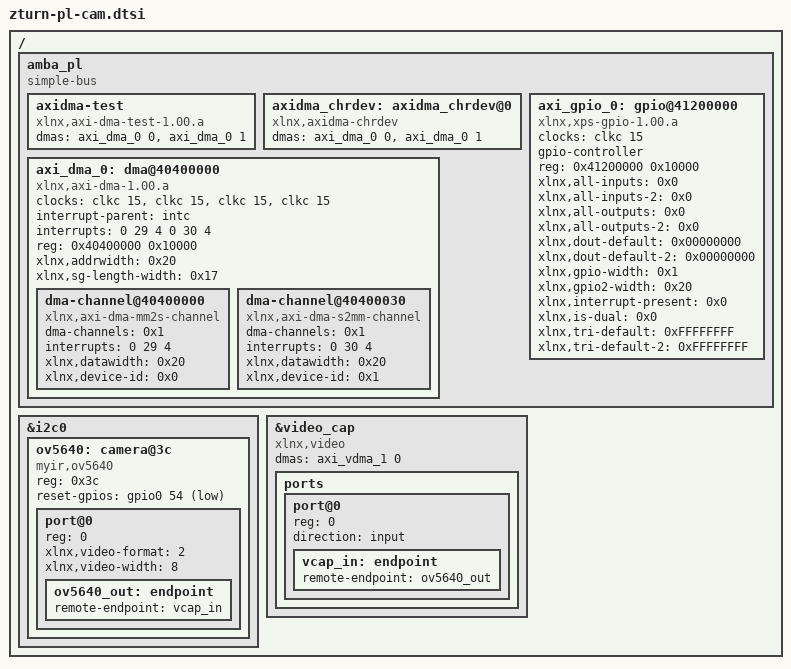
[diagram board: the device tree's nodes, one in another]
/*
 * CAUTION: This file is automatically generated by Xilinx.
 * Version:  
 * Today is: Mon Nov 19 09:26:09 2018
 */


/ {
	amba_pl: amba_pl {
		#address-cells = <1>;
		#size-cells = <1>;
		compatible = "simple-bus";
		ranges ;
		
		axidma-test{
			compatible = "xlnx,axi-dma-test-1.00.a";
			dmas = <&axi_dma_0 0 &axi_dma_0 1>;
			dma-names = "axidma0", "axidma1";
		};
		
		axidma_chrdev: axidma_chrdev@0 {
	    compatible = "xlnx,axidma-chrdev";
	    dmas = <&axi_dma_0 0 &axi_dma_0 1>;
	    dma-names = "tx_channel", "rx_channel";
		};
		
		axi_dma_0: dma@40400000 {
			#dma-cells = <1>;
			clock-names = "s_axi_lite_aclk", "m_axi_sg_aclk", "m_axi_mm2s_aclk", "m_axi_s2mm_aclk";
			clocks = <&clkc 15>, <&clkc 15>, <&clkc 15>, <&clkc 15>;
			compatible = "xlnx,axi-dma-1.00.a";
			interrupt-names = "mm2s_introut", "s2mm_introut";
			interrupt-parent = <&intc>;
			interrupts = <0 29 4 0 30 4>;
			reg = <0x40400000 0x10000>;
			xlnx,addrwidth = <0x20>;
			xlnx,sg-length-width = <0x17>;
			dma-channel@40400000 {
				compatible = "xlnx,axi-dma-mm2s-channel";
				dma-channels = <0x1>;
				interrupts = <0 29 4>;
				xlnx,datawidth = <0x20>;
				xlnx,device-id = <0x0>;
			};
			dma-channel@40400030 {
				compatible = "xlnx,axi-dma-s2mm-channel";
				dma-channels = <0x1>;
				interrupts = <0 30 4>;
				xlnx,datawidth = <0x20>;
				xlnx,device-id = <0x1>;
			};
		};
		
		axi_gpio_0: gpio@41200000 {
			#gpio-cells = <3>;
			clock-names = "s_axi_aclk";
			clocks = <&clkc 15>;
			compatible = "xlnx,xps-gpio-1.00.a";
			gpio-controller ;
			reg = <0x41200000 0x10000>;
			xlnx,all-inputs = <0x0>;
			xlnx,all-inputs-2 = <0x0>;
			xlnx,all-outputs = <0x0>;
			xlnx,all-outputs-2 = <0x0>;
			xlnx,dout-default = <0x00000000>;
			xlnx,dout-default-2 = <0x00000000>;
			xlnx,gpio-width = <0x1>;
			xlnx,gpio2-width = <0x20>;
			xlnx,interrupt-present = <0x0>;
			xlnx,is-dual = <0x0>;
			xlnx,tri-default = <0xFFFFFFFF>;
			xlnx,tri-default-2 = <0xFFFFFFFF>;
		};
		
	};

	&i2c0 {
		ov5640: camera@3c {
			compatible = "myir,ov5640";
			reg = <0x3c>;

			reset-gpios = <&gpio0 54 1>;

			status = "okay";

			#address-cells = <1>;
			#size-cells = <0>;

			port@0 {
				reg = <0>;

				xlnx,video-format = <2>;
				xlnx,video-width = <8>;

				ov5640_out: endpoint {
					remote-endpoint = <&vcap_in>;
				};
			};
		};

		// ov2659: camera@30 {
		// 	compatible = "myir,ov2659";
		// 	reg = <0x30>;

		// 	reset-gpios = <&gpio0 54 1>;

		// 	status = "disable";

		// 	#address-cells = <1>;
		// 	#size-cells = <0>;

		// 	port@0 {
		// 		reg = <0>;

		// 		xlnx,video-format = <2>;
		// 		xlnx,video-width = <8>;

		// 		ov2659_out: endpoint {
		// 			remote-endpoint = <&vcap_in>;
		// 		};
		// 	};
		// };
	};

	&video_cap {
		compatible = "xlnx,video";
		status = "okay";

		dmas = <&axi_vdma_1 0>;
		dma-names = "port0";

		ports {
			#address-cells = <1>;
			#size-cells = <0>;

			port@0 {
				reg = <0>;
				direction = "input";

				vcap_in: endpoint {
					remote-endpoint = <&ov5640_out>;
				};
			};
		};
	};
};
